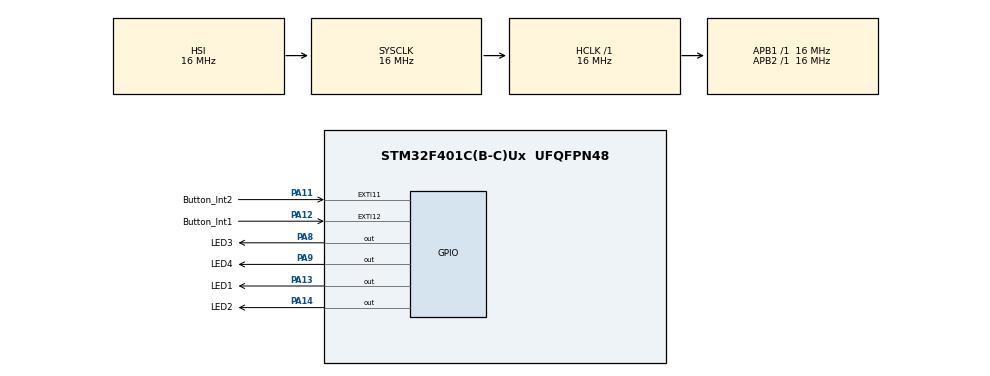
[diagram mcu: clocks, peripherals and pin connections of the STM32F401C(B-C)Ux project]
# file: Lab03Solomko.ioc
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Mcu.Family=STM32F4
Mcu.Name=STM32F401C(B-C)Ux
Mcu.Package=UFQFPN48
NVIC.EXTI15_10_IRQn=true\:0\:0\:false\:true\:true\:1\:true\:true\:true
NVIC.PriorityGroup=NVIC_PRIORITYGROUP_4
PA11.GPIO_Label=Button_Int2
PA11.Signal=GPXTI11
PA12.GPIO_Label=Button_Int1
PA12.Signal=GPXTI12
PA13.GPIO_Label=LED1
PA13.PinState=GPIO_PIN_SET
PA13.Signal=GPIO_Output
PA14.GPIO_Label=LED2
PA14.PinState=GPIO_PIN_SET
PA14.Signal=GPIO_Output
PA8.GPIO_Label=LED3
PA8.PinState=GPIO_PIN_SET
PA8.Signal=GPIO_Output
PA9.GPIO_Label=LED4
PA9.PinState=GPIO_PIN_SET
PA9.Signal=GPIO_Output
ProjectManager.HeapSize=0x200
ProjectManager.StackSize=0x400
ProjectManager.TargetToolchain=STM32CubeIDE
RCC.AHBFreq_Value=16000000
RCC.APB1Freq_Value=16000000
RCC.APB2Freq_Value=16000000
RCC.CortexFreq_Value=16000000
RCC.HSE_VALUE=25000000
RCC.HSI_VALUE=16000000
RCC.LSE_VALUE=32768
RCC.SYSCLKFreq_VALUE=16000000
RCC.VCOOutputFreq_Value=192000000
board=custom

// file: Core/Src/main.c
/* USER CODE BEGIN Header */
/**
  ******************************************************************************
  * @file           : main.c
  * @brief          : Main program body
  ******************************************************************************
  * @attention
  *
  * Copyright (c) 2023 STMicroelectronics.
  * All rights reserved.
  *
  * This software is licensed under terms that can be found in the LICENSE file
  * in the root directory of this software component.
  * If no LICENSE file comes with this software, it is provided AS-IS.
  *
  ******************************************************************************
  */
/* USER CODE END Header */
#include "main.h"
#include "gpio.h"

void SystemClock_Config(void);
static void MX_NVIC_Init(void);

/* USER CODE BEGIN 0 */
		int GPIO_PIN[] = { LED1_Pin, LED2_Pin, LED3_Pin, LED4_Pin };
		int button1_flag = 0;
		int button2_flag = 0;
		int LED_Lenght = 3;
		int i = 0;

	void def(){
		for(int i = 0; i < 4; i++)
			HAL_GPIO_WritePin(GPIOA, GPIO_PIN[i], 1);
		}
/* USER CODE END 0 */

int main(void)
{

  /* MCU Configuration--------------------------------------------------------*/

  /* Reset of all peripherals, Initializes the Flash interface and the Systick. */
  HAL_Init();

  /* Configure the system clock */
  SystemClock_Config();

  /* Initialize all configured peripherals */
  MX_GPIO_Init();

  /* Initialize interrupts */
  MX_NVIC_Init();

  /* Infinite loop */
  while (1)
  {
	  	//TASK
	  	if (button1_flag == 1){
	  		HAL_GPIO_WritePin(GPIOA, GPIO_PIN[i], 0);
	  		i++;
	  		if(i > LED_Lenght) i = LED_Lenght;
	  		button1_flag = 0;
	  	}

	  	if (button2_flag == 1){
	  		HAL_GPIO_WritePin(GPIOA, GPIO_PIN[i], 1);
	  		i--;
	  		if(i < 0) i = 0;
	  		button2_flag = 0;
	  	}
  }
}

void SystemClock_Config(void)
{
  RCC_OscInitTypeDef RCC_OscInitStruct = {0};
  RCC_ClkInitTypeDef RCC_ClkInitStruct = {0};

  /** Configure the main internal regulator output voltage
  */
  __HAL_RCC_PWR_CLK_ENABLE();
  __HAL_PWR_VOLTAGESCALING_CONFIG(PWR_REGULATOR_VOLTAGE_SCALE2);

  /** Initializes the RCC Oscillators according to the specified parameters
  * in the RCC_OscInitTypeDef structure.
  */
  RCC_OscInitStruct.OscillatorType = RCC_OSCILLATORTYPE_HSI;
  RCC_OscInitStruct.HSIState = RCC_HSI_ON;
  RCC_OscInitStruct.HSICalibrationValue = RCC_HSICALIBRATION_DEFAULT;
  RCC_OscInitStruct.PLL.PLLState = RCC_PLL_NONE;
  if (HAL_RCC_OscConfig(&RCC_OscInitStruct) != HAL_OK)
  {
    Error_Handler();
  }

  /** Initializes the CPU, AHB and APB buses clocks
  */
  RCC_ClkInitStruct.ClockType = RCC_CLOCKTYPE_HCLK|RCC_CLOCKTYPE_SYSCLK
                              |RCC_CLOCKTYPE_PCLK1|RCC_CLOCKTYPE_PCLK2;
  RCC_ClkInitStruct.SYSCLKSource = RCC_SYSCLKSOURCE_HSI;
  RCC_ClkInitStruct.AHBCLKDivider = RCC_SYSCLK_DIV1;
  RCC_ClkInitStruct.APB1CLKDivider = RCC_HCLK_DIV1;
  RCC_ClkInitStruct.APB2CLKDivider = RCC_HCLK_DIV1;

  if (HAL_RCC_ClockConfig(&RCC_ClkInitStruct, FLASH_LATENCY_0) != HAL_OK)
  {
    Error_Handler();
  }
}

/**
  * @brief NVIC Configuration.
  * @retval None
  */
static void MX_NVIC_Init(void)
{
  /* EXTI15_10_IRQn interrupt configuration */
  HAL_NVIC_SetPriority(EXTI15_10_IRQn, 0, 0);
  HAL_NVIC_EnableIRQ(EXTI15_10_IRQn);
}

/* USER CODE BEGIN 4 */
void HAL_GPIO_EXTI_Callback(uint16_t GPIO_Pin){

	if (GPIO_Pin == Button_Int1_Pin) button1_flag = 1;
	if (GPIO_Pin == Button_Int2_Pin) button2_flag = 1;

}
/* USER CODE END 4 */

void Error_Handler(void)
{
  __disable_irq();
  while (1)
  {
  }
}
